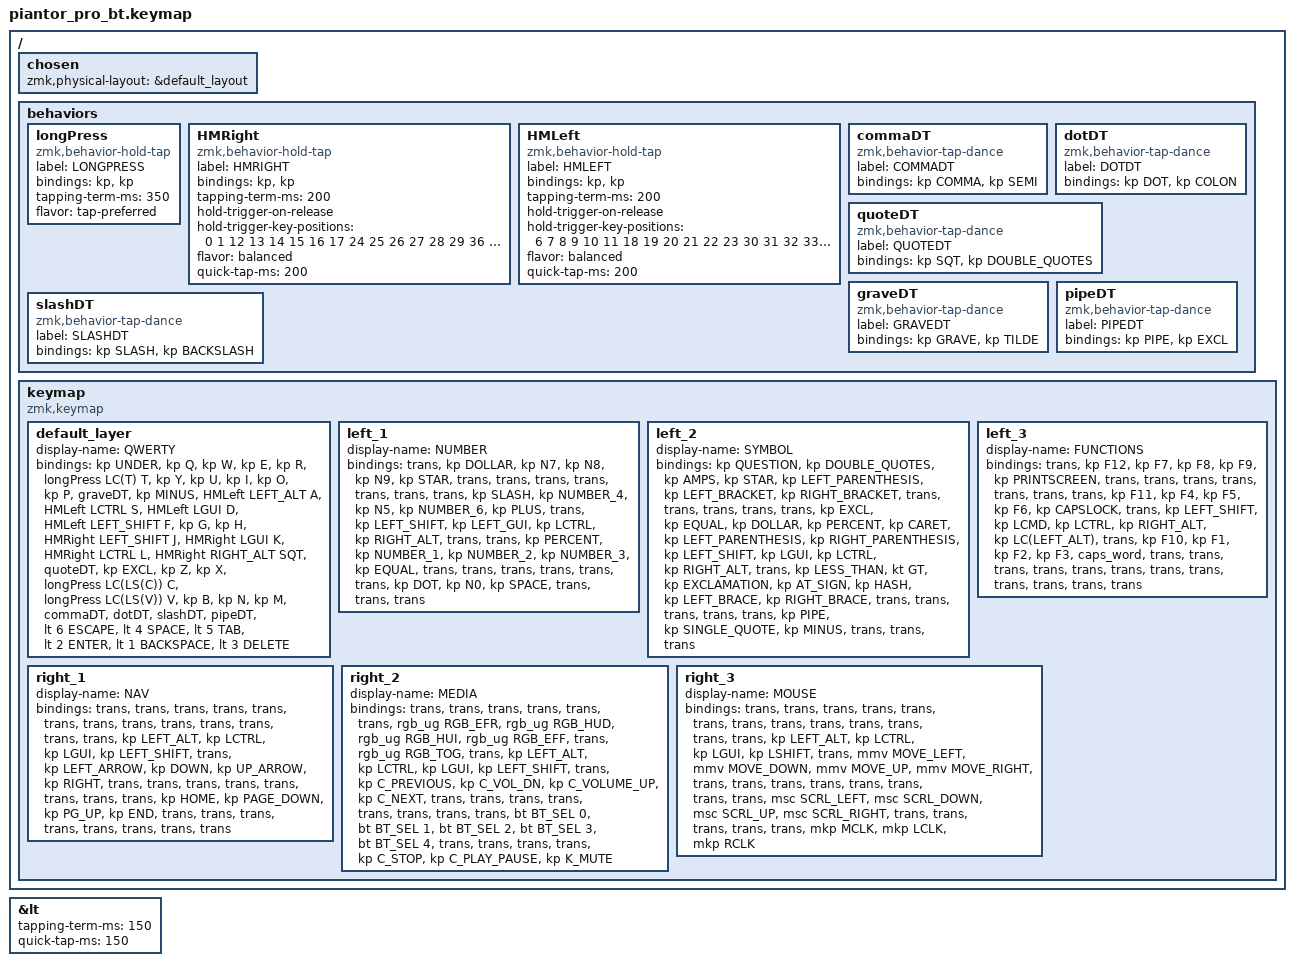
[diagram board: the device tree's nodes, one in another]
/*
 * Copyright (c) 2020 The ZMK Contributors
 *
 * SPDX-License-Identifier: MIT
 */

#include <behaviors.dtsi>
#include <dt-bindings/zmk/bt.h>
#include <dt-bindings/zmk/keys.h>
#include <dt-bindings/zmk/pointing.h>
#include <dt-bindings/zmk/rgb.h>

&lt {
    tapping-term-ms = <150>;
    quick-tap-ms = <150>;
};

/ {
    chosen { zmk,physical-layout = &default_layout; };
};

/ {
    behaviors {
        longPress: longPress {
            compatible = "zmk,behavior-hold-tap";
            label = "LONGPRESS";
            bindings = <&kp>, <&kp>;

            #binding-cells = <2>;
            tapping-term-ms = <350>;
            flavor = "tap-preferred";
        };

        HMRight: HMRight {
            compatible = "zmk,behavior-hold-tap";
            label = "HMRIGHT";
            bindings = <&kp>, <&kp>;

            #binding-cells = <2>;
            tapping-term-ms = <200>;
            hold-trigger-on-release;
            hold-trigger-key-positions = <0 1 12 13 14 15 16 17 24 25 26 27 28 29 36 37 38 2 3 4 5>;
            flavor = "balanced";
            quick-tap-ms = <200>;
        };

        HMLeft: HMLeft {
            compatible = "zmk,behavior-hold-tap";
            label = "HMLEFT";
            bindings = <&kp>, <&kp>;

            #binding-cells = <2>;
            tapping-term-ms = <200>;
            hold-trigger-on-release;
            hold-trigger-key-positions = <6 7 8 9 10 11 18 19 20 21 22 23 30 31 32 33 34 35 39 40 41>;
            flavor = "balanced";
            quick-tap-ms = <200>;
        };

        commaDT: commaDT {
            compatible = "zmk,behavior-tap-dance";
            label = "COMMADT";
            #binding-cells = <0>;
            bindings = <&kp COMMA>, <&kp SEMI>;
        };

        dotDT: dotDT {
            compatible = "zmk,behavior-tap-dance";
            label = "DOTDT";
            #binding-cells = <0>;
            bindings = <&kp DOT>, <&kp COLON>;
        };

        quoteDT: quoteDT {
            compatible = "zmk,behavior-tap-dance";
            label = "QUOTEDT";
            #binding-cells = <0>;
            bindings = <&kp SQT>, <&kp DOUBLE_QUOTES>;
        };

        graveDT: graveDT {
            compatible = "zmk,behavior-tap-dance";
            label = "GRAVEDT";
            #binding-cells = <0>;
            bindings = <&kp GRAVE>, <&kp TILDE>;
        };

        slashDT: slashDT {
            compatible = "zmk,behavior-tap-dance";
            label = "SLASHDT";
            #binding-cells = <0>;
            bindings = <&kp SLASH>, <&kp BACKSLASH>;
        };

        pipeDT: pipeDT {
            compatible = "zmk,behavior-tap-dance";
            label = "PIPEDT";
            #binding-cells = <0>;
            bindings = <&kp PIPE>, <&kp EXCL>;
        };
    };

    keymap {
        compatible = "zmk,keymap";

        default_layer {
            display-name = "QWERTY";
            bindings = <
&kp UNDER  &kp Q  &kp W  &kp E  &kp R  &longPress LC(T) T  &kp Y  &kp U  &kp I  &kp O  &kp P  &graveDT  &kp MINUS  &HMLeft LEFT_ALT A  &HMLeft LCTRL S  &HMLeft LGUI D  &HMLeft LEFT_SHIFT F  &kp G  &kp H  &HMRight LEFT_SHIFT J  &HMRight LGUI K  &HMRight LCTRL L  &HMRight RIGHT_ALT SQT  &quoteDT  &kp EXCL  &kp Z  &kp X  &longPress LC(LS(C)) C  &longPress LC(LS(V)) V  &kp B  &kp N  &kp M  &commaDT  &dotDT  &slashDT  &pipeDT  &lt 6 ESCAPE  &lt 4 SPACE  &lt 5 TAB  &lt 2 ENTER  &lt 1 BACKSPACE  &lt 3 DELETE
            >;
        };

        left_1 {
            display-name = "NUMBER";
            bindings = <
&trans  &kp DOLLAR  &kp N7  &kp N8  &kp N9  &kp STAR  &trans  &trans  &trans  &trans  &trans  &trans  &trans  &kp SLASH  &kp NUMBER_4  &kp N5  &kp NUMBER_6  &kp PLUS  &trans  &kp LEFT_SHIFT  &kp LEFT_GUI  &kp LCTRL  &kp RIGHT_ALT  &trans  &trans  &kp PERCENT  &kp NUMBER_1  &kp NUMBER_2  &kp NUMBER_3  &kp EQUAL  &trans  &trans  &trans  &trans  &trans  &trans  &kp DOT  &kp N0  &kp SPACE  &trans  &trans  &trans
            >;
        };

        left_2 {
            display-name = "SYMBOL";
            bindings = <
&kp QUESTION  &kp DOUBLE_QUOTES  &kp AMPS  &kp STAR  &kp LEFT_PARENTHESIS  &kp LEFT_BRACKET  &kp RIGHT_BRACKET  &trans  &trans  &trans  &trans  &trans  &kp EXCL  &kp EQUAL  &kp DOLLAR  &kp PERCENT  &kp CARET  &kp LEFT_PARENTHESIS  &kp RIGHT_PARENTHESIS  &kp LEFT_SHIFT  &kp LGUI  &kp LCTRL  &kp RIGHT_ALT  &trans  &kp LESS_THAN  &kt GT  &kp EXCLAMATION  &kp AT_SIGN  &kp HASH  &kp LEFT_BRACE  &kp RIGHT_BRACE  &trans  &trans  &trans  &trans  &trans  &kp PIPE  &kp SINGLE_QUOTE  &kp MINUS  &trans  &trans  &trans
            >;
        };

        left_3 {
            display-name = "FUNCTIONS";
            bindings = <
&trans  &kp F12  &kp F7  &kp F8  &kp F9  &kp PRINTSCREEN  &trans  &trans  &trans  &trans  &trans  &trans  &trans  &kp F11  &kp F4  &kp F5  &kp F6  &kp CAPSLOCK  &trans  &kp LEFT_SHIFT  &kp LCMD  &kp LCTRL  &kp RIGHT_ALT  &kp LC(LEFT_ALT)  &trans  &kp F10  &kp F1  &kp F2  &kp F3  &caps_word  &trans  &trans  &trans  &trans  &trans  &trans  &trans  &trans  &trans  &trans  &trans  &trans
            >;
        };

        right_1 {
            display-name = "NAV";
            bindings = <
&trans  &trans  &trans  &trans  &trans  &trans  &trans  &trans  &trans  &trans  &trans  &trans  &trans  &kp LEFT_ALT  &kp LCTRL  &kp LGUI  &kp LEFT_SHIFT  &trans  &kp LEFT_ARROW  &kp DOWN  &kp UP_ARROW  &kp RIGHT  &trans  &trans  &trans  &trans  &trans  &trans  &trans  &trans  &kp HOME  &kp PAGE_DOWN  &kp PG_UP  &kp END  &trans  &trans  &trans  &trans  &trans  &trans  &trans  &trans
            >;
        };

        right_2 {
            display-name = "MEDIA";
            bindings = <
&trans  &trans  &trans  &trans  &trans  &trans  &rgb_ug RGB_EFR  &rgb_ug RGB_HUD  &rgb_ug RGB_HUI  &rgb_ug RGB_EFF  &trans  &rgb_ug RGB_TOG  &trans  &kp LEFT_ALT  &kp LCTRL  &kp LGUI  &kp LEFT_SHIFT  &trans  &kp C_PREVIOUS  &kp C_VOL_DN  &kp C_VOLUME_UP  &kp C_NEXT  &trans  &trans  &trans  &trans  &trans  &trans  &trans  &trans  &bt BT_SEL 0  &bt BT_SEL 1  &bt BT_SEL 2  &bt BT_SEL 3  &bt BT_SEL 4  &trans  &trans  &trans  &trans  &kp C_STOP  &kp C_PLAY_PAUSE  &kp K_MUTE
            >;
        };

        right_3 {
            display-name = "MOUSE";
            bindings = <
&trans  &trans  &trans  &trans  &trans  &trans  &trans  &trans  &trans  &trans  &trans  &trans  &trans  &kp LEFT_ALT  &kp LCTRL  &kp LGUI  &kp LSHIFT  &trans  &mmv MOVE_LEFT  &mmv MOVE_DOWN  &mmv MOVE_UP  &mmv MOVE_RIGHT  &trans  &trans  &trans  &trans  &trans  &trans  &trans  &trans  &msc SCRL_LEFT  &msc SCRL_DOWN  &msc SCRL_UP  &msc SCRL_RIGHT  &trans  &trans  &trans  &trans  &trans  &mkp MCLK  &mkp LCLK  &mkp RCLK
            >;
        };
    };
};
